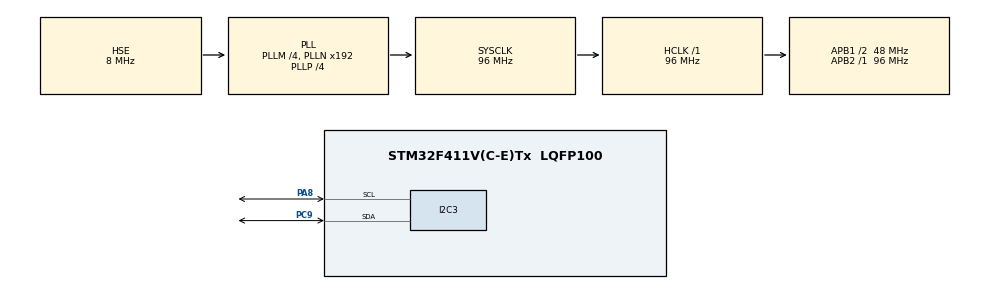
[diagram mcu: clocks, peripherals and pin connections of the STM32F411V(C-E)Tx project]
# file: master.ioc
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Mcu.Family=STM32F4
Mcu.Name=STM32F411V(C-E)Tx
Mcu.Package=LQFP100
NVIC.I2C3_ER_IRQn=true\:0\:0\:false\:false\:true\:true\:true\:true
NVIC.I2C3_EV_IRQn=true\:0\:0\:false\:false\:true\:true\:true\:true
NVIC.PriorityGroup=NVIC_PRIORITYGROUP_0
PA13.Mode=Serial_Wire
PA13.Signal=SYS_JTMS-SWDIO
PA14.Mode=Serial_Wire
PA14.Signal=SYS_JTCK-SWCLK
PA8.GPIO_Speed=GPIO_SPEED_FREQ_HIGH
PA8.Mode=I2C
PA8.Signal=I2C3_SCL
PC9.GPIO_Speed=GPIO_SPEED_FREQ_HIGH
PC9.Mode=I2C
PC9.Signal=I2C3_SDA
PH0\ -\ OSC_IN.Mode=HSE-External-Oscillator
PH0\ -\ OSC_IN.Signal=RCC_OSC_IN
PH1\ -\ OSC_OUT.Mode=HSE-External-Oscillator
PH1\ -\ OSC_OUT.Signal=RCC_OSC_OUT
ProjectManager.HeapSize=0x200
ProjectManager.StackSize=0x400
ProjectManager.TargetToolchain=STM32CubeIDE
RCC.48MHZClocksFreq_Value=48000000
RCC.AHBFreq_Value=96000000
RCC.APB1CLKDivider=RCC_HCLK_DIV2
RCC.APB1Freq_Value=48000000
RCC.APB1TimFreq_Value=96000000
RCC.APB2Freq_Value=96000000
RCC.APB2TimFreq_Value=96000000
RCC.CortexFreq_Value=96000000
RCC.HCLKFreq_Value=96000000
RCC.HSE_VALUE=8000000
RCC.HSI_VALUE=16000000
RCC.LSE_VALUE=32768
RCC.PLLI2SM=5
RCC.PLLI2SN=200
RCC.PLLM=4
RCC.PLLP=RCC_PLLP_DIV4
RCC.PLLQ=8
RCC.PLLSourceVirtual=RCC_PLLSOURCE_HSE
RCC.SYSCLKFreq_VALUE=96000000
RCC.SYSCLKSource=RCC_SYSCLKSOURCE_PLLCLK
RCC.VCOOutputFreq_Value=384000000
board=STM32F411E-DISCO

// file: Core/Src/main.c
/* USER CODE BEGIN Header */
/**
 ******************************************************************************
 * @file           : main.c
 * @brief          : Main program body
 ******************************************************************************
 * @attention
 *
 * Copyright (c) 2025 STMicroelectronics.
 * All rights reserved.
 *
 * This software is licensed under terms that can be found in the LICENSE file
 * in the root directory of this software component.
 * If no LICENSE file comes with this software, it is provided AS-IS.
 *
 ******************************************************************************
 */
/* USER CODE END Header */
#include "main.h"

/* USER CODE BEGIN Includes */
#include <stdio.h>
#include <math.h>
/* USER CODE END Includes */

/* USER CODE BEGIN PTD */
typedef struct {
	float x;
	float y;
	float theta;
	float speed;
	uint8_t command;    // 1=move, 0=stop
} movement_command_t;

/* USER CODE END PTD */

/* USER CODE BEGIN PD */
#define SLAVE_1_ADDR 0x10
#define SLAVE_2_ADDR 0x20
#define SLAVE_3_ADDR 0x30

/* USER CODE END PD */

I2C_HandleTypeDef hi2c3;

void SystemClock_Config(void);
static void MX_GPIO_Init(void);
static void MX_I2C3_Init(void);

/* USER CODE BEGIN 0 */
// Simplified send function (no need for complex reset with 4.7kΩ)
void SendMovementToAll(float x, float y, float theta, float speed, uint8_t cmd) {
	movement_command_t move;
	move.x = x;
	move.y = y;
	move.theta = theta;
	move.speed = speed;
	move.command = cmd;

	uint8_t addrs[] =
			{ SLAVE_1_ADDR << 1, SLAVE_2_ADDR << 1, SLAVE_3_ADDR << 1 };
	uint8_t success_count = 0;

//    printf("Send: vx=%.2f vy=%.2f ω=%.2f cmd=%d\n", vx, vy, omega, cmd);

	for (int i = 0; i < 3; i++) {
		HAL_StatusTypeDef status = HAL_I2C_Master_Transmit_IT(&hi2c3, addrs[i],
				(uint8_t*) &move, sizeof(move)); // Shorter timeout with 4.7kΩ

		if (status == HAL_OK) {
			printf("R%d:OK ", i + 1);
			success_count++;
		} else {
			printf("R%d:FAIL(%d) ", i + 1, status);

			if (status == HAL_BUSY) {
				// Simple retry for HAL_BUSY
				HAL_Delay(10);
				status = HAL_I2C_Master_Transmit_IT(&hi2c3, addrs[i],
						(uint8_t*) &move, sizeof(move));
				if (status == HAL_OK) {
					printf("R%d:RETRY_OK ", i + 1);
					success_count++;
				}
			}
		}

		HAL_Delay(10); // Short delay between transmissions
	}

	printf("→ %d/3 OK\n", success_count);
}

void StopAll(void) {
	SendMovementToAll(0, 0, 0, 0, 0);
}

void MoveForward(float x, float speed) {
	SendMovementToAll(x, 0, 0, speed, 1);
}

void MoveSideways(float y, float speed) {
	SendMovementToAll(0, y, 0, speed, 1);
}

void Rotate(float theta, float speed) {
	SendMovementToAll(0, 0, theta, speed, 1);
}

void TestBasicMovements(void) {
	printf("=== Basic Movement Test ===\n");

	// Forward
	printf("Forward...\n");
	MoveForward(0.5f, 0.5f);
	HAL_Delay(2000);
	StopAll();
	HAL_Delay(500);

	// Backward
	printf("Backward...\n");
	MoveForward(-0.5f, 0.5f);
	HAL_Delay(2000);
	StopAll();
	HAL_Delay(500);

	// Sideways right
	printf("Right...\n");
	MoveSideways(0.5f, 0.5f);
	HAL_Delay(2000);
	StopAll();
	HAL_Delay(500);

	// Sideways left
	printf("Left...\n");
	MoveSideways(-0.5f, 0.5f);
	HAL_Delay(2000);
	StopAll();
	HAL_Delay(500);

	// Rotate clockwise
	printf("Rotate CW...\n");
	Rotate(0.5f, 0.5f);
	HAL_Delay(2000);
	StopAll();
	HAL_Delay(500);

	// Rotate counter-clockwise
	printf("Rotate CCW...\n");
	Rotate(-0.5f, 0.5f);
	HAL_Delay(2000);
	StopAll();
	HAL_Delay(1000);

	printf("=== Test Complete ===\n");
}
/* USER CODE END 0 */

int main(void) {

	/* MCU Configuration--------------------------------------------------------*/

	/* Reset of all peripherals, Initializes the Flash interface and the Systick. */
	HAL_Init();

	/* Configure the system clock */
	SystemClock_Config();

	/* Initialize all configured peripherals */
	MX_GPIO_Init();
	MX_I2C3_Init();
	/* USER CODE BEGIN 2 */
	TestBasicMovements();
	/* USER CODE END 2 */

	/* Infinite loop */
	/* USER CODE BEGIN WHILE */
	while (1) {
//		MoveForward(0.5f, 0.5f);
		/* USER CODE END WHILE */

	}
}

void SystemClock_Config(void) {
	RCC_OscInitTypeDef RCC_OscInitStruct = { 0 };
	RCC_ClkInitTypeDef RCC_ClkInitStruct = { 0 };

	/** Configure the main internal regulator output voltage
	 */
	__HAL_RCC_PWR_CLK_ENABLE();
	__HAL_PWR_VOLTAGESCALING_CONFIG(PWR_REGULATOR_VOLTAGE_SCALE1);

	/** Initializes the RCC Oscillators according to the specified parameters
	 * in the RCC_OscInitTypeDef structure.
	 */
	RCC_OscInitStruct.OscillatorType = RCC_OSCILLATORTYPE_HSE;
	RCC_OscInitStruct.HSEState = RCC_HSE_ON;
	RCC_OscInitStruct.PLL.PLLState = RCC_PLL_ON;
	RCC_OscInitStruct.PLL.PLLSource = RCC_PLLSOURCE_HSE;
	RCC_OscInitStruct.PLL.PLLM = 4;
	RCC_OscInitStruct.PLL.PLLN = 192;
	RCC_OscInitStruct.PLL.PLLP = RCC_PLLP_DIV4;
	RCC_OscInitStruct.PLL.PLLQ = 8;
	if (HAL_RCC_OscConfig(&RCC_OscInitStruct) != HAL_OK) {
		Error_Handler();
	}

	/** Initializes the CPU, AHB and APB buses clocks
	 */
	RCC_ClkInitStruct.ClockType = RCC_CLOCKTYPE_HCLK | RCC_CLOCKTYPE_SYSCLK
			| RCC_CLOCKTYPE_PCLK1 | RCC_CLOCKTYPE_PCLK2;
	RCC_ClkInitStruct.SYSCLKSource = RCC_SYSCLKSOURCE_PLLCLK;
	RCC_ClkInitStruct.AHBCLKDivider = RCC_SYSCLK_DIV1;
	RCC_ClkInitStruct.APB1CLKDivider = RCC_HCLK_DIV2;
	RCC_ClkInitStruct.APB2CLKDivider = RCC_HCLK_DIV1;

	if (HAL_RCC_ClockConfig(&RCC_ClkInitStruct, FLASH_LATENCY_3) != HAL_OK) {
		Error_Handler();
	}
}

static void MX_I2C3_Init(void) {

	hi2c3.Instance = I2C3;
	hi2c3.Init.ClockSpeed = 100000;
	hi2c3.Init.DutyCycle = I2C_DUTYCYCLE_2;
	hi2c3.Init.OwnAddress1 = 0;
	hi2c3.Init.AddressingMode = I2C_ADDRESSINGMODE_7BIT;
	hi2c3.Init.DualAddressMode = I2C_DUALADDRESS_DISABLE;
	hi2c3.Init.OwnAddress2 = 0;
	hi2c3.Init.GeneralCallMode = I2C_GENERALCALL_DISABLE;
	hi2c3.Init.NoStretchMode = I2C_NOSTRETCH_DISABLE;
	if (HAL_I2C_Init(&hi2c3) != HAL_OK) {
		Error_Handler();
	}

}

static void MX_GPIO_Init(void) {

	/* GPIO Ports Clock Enable */
	__HAL_RCC_GPIOH_CLK_ENABLE();
	__HAL_RCC_GPIOC_CLK_ENABLE();
	__HAL_RCC_GPIOA_CLK_ENABLE();

}

void Error_Handler(void) {
	__disable_irq();
	while (1) {
	}
}
